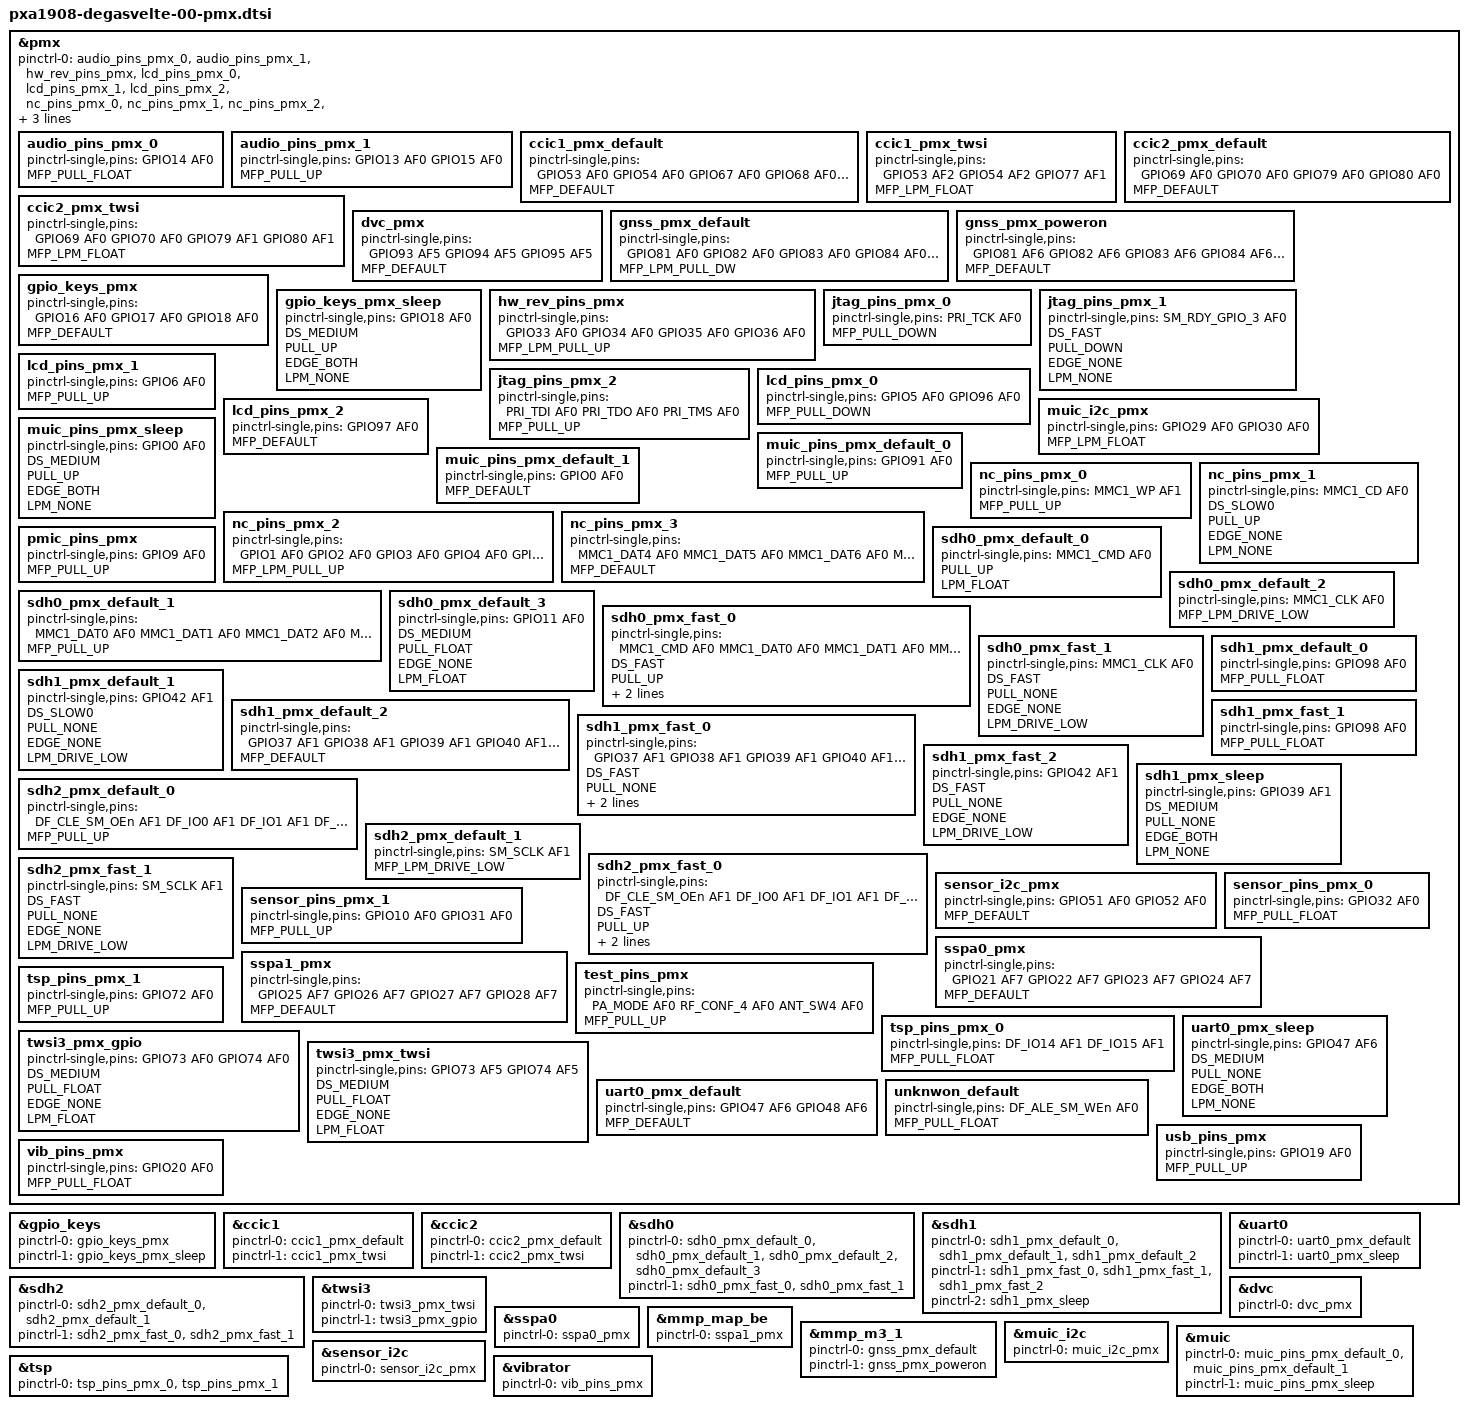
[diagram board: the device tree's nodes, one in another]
/* arch/arm64/boot/dts/pxa1908-degasvelte-00-pmx.dtsi
 *
 *	Copyright (C) 2014 Marvell Technology Group Ltd.
 *	Copyright (C) 2014 Samsung Electronics Co, Ltd.
 *
 *	Most of configurations are taken from J1-LTE
 *
 *	This program is free software; you can redistribute it and/or modify
 *	it under the terms of the GNU General Public License version 2 as
 *	published by the Free Software Foundation.
 */

#ifndef __PXA1908_DEGASVELTE_00_PMX_DTSI__
#define __PXA1908_DEGASVELTE_00_PMX_DTSI__

&pmx {
	/* >>>BEGIN: audio_pins_pmx */
	audio_pins_pmx_0: audio_pins_pmx_0 {	/* default */
		pinctrl-single,pins = <
			GPIO14			AF0	/* EAR_G_DET (GPIO[14]) */
		>;
		MFP_PULL_FLOAT;
	};

	audio_pins_pmx_1: audio_pins_pmx_1 {	/* default */
		pinctrl-single,pins = <
			GPIO13			AF0	/* EAR_SW (GPIO[13]) */
			GPIO15			AF0	/* EAR_DET_3.5 (GPIO[15]) */
		>;
		MFP_PULL_UP;
	};
	/* <<<END: audio_pins_pmx */

	/* >>>BEGIN: ccic1_pmx_default */
	ccic1_pmx_default: ccic1_pmx_default {	/* default */
		pinctrl-single,pins = <
			GPIO53			AF0	/* 3M_CAM_SCL_1P8 (GPIO[53]) */
			GPIO54			AF0	/* 3M_CAM_SDA_1P8 (GPIO[54]) */
			GPIO67			AF0	/* 3M_CAM_nRST (GPIO[67]) */
			GPIO68			AF0	/* 3M_CAM_STBY (GPIO[68]) */
			GPIO77			AF1	/* CAM_MCLK (CAM_MCLK) */
		>;
		MFP_DEFAULT;
	};
	/* <<<END: ccic1_pmx_default */

	/* >>>BEGIN: ccic1_pmx_twsi */
	ccic1_pmx_twsi: ccic1_pmx_twsi {	/* twsi */
		pinctrl-single,pins = <
			GPIO53			AF2	/* 3M_CAM_SCL_1P8 (CI2C_SCL_1) */
			GPIO54			AF2	/* 3M_CAM_SDA_1P8 (CI2C_SDA_1) */
			GPIO77			AF1	/* CAM_MCLK (CAM_MCLK) */
		>;
		MFP_LPM_FLOAT;
	};
	/* <<<END: ccic1_pmx_twsi */

	/* >>>BEGIN: ccic2_pmx_default */
	ccic2_pmx_default: ccic2_pmx_default {	/* default */
		pinctrl-single,pins = <
			GPIO69			AF0	/* VT_CAM_nRST (GPIO[69]) */
			GPIO70			AF0	/* VT_CAM_nSTBY (GPIO[70]) */
			GPIO79			AF0	/* VT_CAM_SCL_1P8 (GPIO[79]) */
			GPIO80			AF0	/* VT_CAM_SDA_1P8 (GPIO[80]) */
		>;
		MFP_DEFAULT;
	};
	/* <<<END: ccic2_pmx_default */

	/* >>>BEGIN: ccic2_pmx_twsi */
	ccic2_pmx_twsi: ccic2_pmx_twsi {	/* twsi */
		pinctrl-single,pins = <
			GPIO69			AF0	/* VT_CAM_nRST (GPIO[69]) */
			GPIO70			AF0	/* VT_CAM_nSTBY (GPIO[70]) */
			GPIO79			AF1	/* VT_CAM_SCL_1P8 (CI2C_SCL_1) */
			GPIO80			AF1	/* VT_CAM_SDA_1P8 (CI2C_SDA_1) */
		>;
		MFP_LPM_FLOAT;
	};
	/* <<<END: ccic2_pmx_twsi */

	/* >>>BEGIN: dvc_pmx */
	dvc_pmx: dvc_pmx {	/* default */
		pinctrl-single,pins = <
			GPIO93			AF5	/* DVC2 (DVL[1]) */
			GPIO94			AF5	/* DVC1 (DVL[0]) */
			GPIO95			AF5	/* DVC3 (DVL[2]) */
		>;
		MFP_DEFAULT;
	};
	/* <<<END: dvc_pmx */

	/* >>>BEGIN: gnss_pmx_default */
	gnss_pmx_default: gnss_pmx_default {	/* default */
		pinctrl-single,pins = <
			GPIO81			AF0	/* GPS_IRQ (GPIO[81]) */
			GPIO82			AF0	/* GPS_RST (GPIO[82]) */
			GPIO83			AF0	/* GPS_CS_N (GPIO[83]) */
			GPIO84			AF0	/* GPS_SYNC_CLK (GPIO[84]) */
			GPIO85			AF0	/* GNSS_RF_SDIN (GPIO[85]) */
		>;
		MFP_LPM_PULL_DW;
	};
	/* <<<END: gnss_pmx_default */

	/* >>>BEGIN: gnss_pmx_poweron */
	gnss_pmx_poweron: gnss_pmx_poweron {	/* poweron */
		pinctrl-single,pins = <
			GPIO81			AF6	/* GPS_IRQ (GNSS_RF_IRQ) */
			GPIO82			AF6	/* GPS_RST (GNSS_RF_RESETn) */
			GPIO83			AF6	/* GPS_CS_N (GNSS_RF_CSn) */
			GPIO84			AF6	/* GPS_SYNC_CLK (GNSS_RF_CLK) */
			GPIO85			AF6	/* GNSS_RF_SDIN (GNSS_RF_DATA) */
		>;
		MFP_DEFAULT;
	};
	/* <<<END: gnss_pmx_poweron */

	/* >>>BEGIN: gpio_keys_pmx */
	gpio_keys_pmx: gpio_keys_pmx {	/* default */
		pinctrl-single,pins = <
			GPIO16			AF0	/* VOL_UP (GPIO[16]) */
			GPIO17			AF0	/* VOL_DN (GPIO[17]) */
			GPIO18			AF0	/* HOME_KEY (GPIO[18]) */
		>;
		MFP_DEFAULT;
	};
	/* <<<END: gpio_keys_pmx */

	/* >>>BEGIN: gpio_keys_pmx_sleep */
	gpio_keys_pmx_sleep: gpio_keys_pmx_sleep {	/* sleep */
		pinctrl-single,pins = <
			GPIO18			AF0	/* HOME_KEY (GPIO[18]) */
		>;
		DS_MEDIUM; PULL_UP; EDGE_BOTH; LPM_NONE;
	};
	/* <<<END: gpio_keys_pmx_sleep */

	/* >>>BEGIN: hw_rev_pins_pmx */
	hw_rev_pins_pmx: hw_rev_pins_pmx {	/* default */
		pinctrl-single,pins = <
			GPIO33			AF0	/* HW_REV0 (GPIO[33]) */
			GPIO34			AF0	/* HW_REV1 (GPIO[34]) */
			GPIO35			AF0	/* HW_REV2 (GPIO[35]) */
			GPIO36			AF0	/* HW_REV3 (GPIO[36]) */
		>;
		MFP_LPM_PULL_UP;
	};
	/* <<<END: hw_rev_pins_pmx */

	/* >>>BEGIN: jtag_pins_pmx */
	jtag_pins_pmx_0: jtag_pins_pmx_0 {	/* default */
		pinctrl-single,pins = <
			PRI_TCK			AF0	/* JTAG_TCK (PRI_TCK) */
		>;
		MFP_PULL_DOWN;
	};

	jtag_pins_pmx_1: jtag_pins_pmx_1 {	/* default */
		pinctrl-single,pins = <
			SM_RDY_GPIO_3		AF0	/* AP_USB_BOOT (SM_RDY) */
		>;
		DS_FAST; PULL_DOWN; EDGE_NONE; LPM_NONE;
	};

	jtag_pins_pmx_2: jtag_pins_pmx_2 {	/* default */
		pinctrl-single,pins = <
			PRI_TDI			AF0	/* JTAG_TDI (PRI_TDI) */
			PRI_TDO			AF0	/* JTAG_TDO (PRI_TDO) */
			PRI_TMS			AF0	/* JTAG_TMS (PRI_TMS) */
		>;
		MFP_PULL_UP;
	};
	/* <<<END: jtag_pins_pmx */

	/* >>>BEGIN: lcd_pins_pmx */
	lcd_pins_pmx_0: lcd_pins_pmx_0 {	/* default */
		pinctrl-single,pins = <
			GPIO5			AF0	/* LCD_3V3_EN (GPIO[5]) */
			GPIO96			AF0	/* LCD_nRST (GPIO[96]) */
		>;
		MFP_PULL_DOWN;
	};

	lcd_pins_pmx_1: lcd_pins_pmx_1 {	/* default */
		pinctrl-single,pins = <
			GPIO6			AF0	/* LCD_ESD_DET (GPIO[6]) */
		>;
		MFP_PULL_UP;
	};

	lcd_pins_pmx_2: lcd_pins_pmx_2 {	/* default */
		pinctrl-single,pins = <
			GPIO97			AF0	/* LCD_BLIC_ON (GPIO[97]) */
		>;
		MFP_DEFAULT;
	};
	/* <<<END: lcd_pins_pmx */

	/* >>>BEGIN: muic_i2c_pmx */
	muic_i2c_pmx: muic_i2c_pmx {	/* default */
		pinctrl-single,pins = <
			GPIO29			AF0	/* MUIC_SCL_1P8 (GPIO[29]) */
			GPIO30			AF0	/* MUIC_SDA_1P8 (GPIO[30]) */
		>;
		MFP_LPM_FLOAT;
	};
	/* <<<END: muic_i2c_pmx */

	/* >>>BEGIN: muic_pins_pmx_default */
	muic_pins_pmx_default_0: muic_pins_pmx_default_0 {	/* default */
		pinctrl-single,pins = <
			GPIO91			AF0	/* UART_BOOT_ON (GPIO[91]) */
		>;
		MFP_PULL_UP;
	};

	muic_pins_pmx_default_1: muic_pins_pmx_default_1 {	/* default */
		pinctrl-single,pins = <
			GPIO0			AF0	/* MUIC_INT (GPIO[0]) */
		>;
		MFP_DEFAULT;
	};
	/* <<<END: muic_pins_pmx_default */

	/* >>>BEGIN: muic_pins_pmx_sleep */
	muic_pins_pmx_sleep: muic_pins_pmx_sleep {	/* sleep */
		pinctrl-single,pins = <
			GPIO0			AF0	/* MUIC_INT (GPIO[0]) */
		>;
		DS_MEDIUM; PULL_UP; EDGE_BOTH; LPM_NONE;
	};
	/* <<<END: muic_pins_pmx_sleep */

	/* >>>BEGIN: nc_pins_pmx */
	nc_pins_pmx_0: nc_pins_pmx_0 {	/* default */
		pinctrl-single,pins = <
			MMC1_WP			AF1	/* NC (GPIO[99]) */
		>;
		MFP_PULL_UP;
	};

	nc_pins_pmx_1: nc_pins_pmx_1 {	/* default */
		pinctrl-single,pins = <
			MMC1_CD			AF0	/* NC (MMC1_CD) */
		>;
		DS_SLOW0; PULL_UP; EDGE_NONE; LPM_NONE;
	};

	nc_pins_pmx_2: nc_pins_pmx_2 {	/* default */
		pinctrl-single,pins = <
			GPIO1			AF0	/* NC (GPIO[1]) */
			GPIO2			AF0	/* NC (GPIO[2]) */
			GPIO3			AF0	/* NC (GPIO[3]) */
			GPIO4			AF0	/* NC (GPIO[4]) */
			GPIO7			AF0	/* NC (GPIO[7]) */
			GPIO8			AF0	/* NC (GPIO[8]) */
			GPIO12			AF0	/* NC (GPIO[12]) */
			GPIO43			AF0	/* NC (GPIO[43]) */
			GPIO44			AF0	/* NC (GPIO[44]) */
			GPIO45			AF0	/* NC (GPIO[45]) */
			GPIO46			AF0	/* NC (GPIO[46]) */
			GPIO49			AF0	/* NC (GPIO[49]) */
			GPIO50			AF0	/* NC (GPIO[50]) */
			GPIO71			AF0	/* NC (GPIO[71]) */
			GPIO75			AF0	/* NC (GPIO[75]) */
			GPIO76			AF0	/* NC (GPIO[76]) */
			GPIO78			AF0	/* NC (GPIO[78]) */
			GPIO86			AF0	/* NC (GPIO[86]) */
			GPIO87			AF0	/* NC (GPIO[87]) */
			GPIO88			AF0	/* NC (GPIO[88]) */
			GPIO89			AF0	/* NC (GPIO[89]) */
			GPIO90			AF0	/* NC (GPIO[90]) */
			GPIO92			AF0	/* NC (GPIO[92]) */
			GPIO124			AF0	/* NC (GPIO[124]) */
			SM_ADV			AF1	/* NC (GPIO[0]) */
			SM_ADVMUX		AF1	/* NC (GPIO[2]) */
			SM_BE0			AF0	/* NC (GPIO[126]) */
			SM_BE1			AF0	/* NC (GPIO[127]) */
			SM_nCS0			AF1	/* NC (GPIO[103]) */
			SM_nCS1			AF1	/* NC (GPIO[104]) */
			DF_nCS1_SM_nCS3		AF1	/* NC (GPIO[102]) */
			DF_RDY0			AF1	/* NC (GPIO[108]) */
			DF_RDY1			AF1	/* NC (GPIO[1]) */
			DF_REn			AF0	/* NC (ND_REn) */
			DF_WEn			AF0	/* NC (ND_WEn) */
		>;
		MFP_LPM_PULL_UP;
	};

	nc_pins_pmx_3: nc_pins_pmx_3 {	/* default */
		pinctrl-single,pins = <
			MMC1_DAT4		AF0	/* NC (MMC1_DAT[4]) */
			MMC1_DAT5		AF0	/* NC (MMC1_DAT[5]) */
			MMC1_DAT6		AF0	/* NC (MMC1_DAT[6]) */
			MMC1_DAT7		AF0	/* NC (MMC1_DAT[7]) */
			DF_IO8			AF1	/* NC (GPIO[100]) */
			DF_IO9			AF1	/* NC (GPIO[66]) */
			DF_IO10			AF1	/* NC (GPIO[65]) */
			DF_IO11			AF1	/* NC (GPIO[64]) */
			DF_IO12			AF1	/* NC (GPIO[63]) */
			DF_IO13			AF1	/* NC (GPIO[62]) */
		>;
		MFP_DEFAULT;
	};
	/* <<<END: nc_pins_pmx */

	/* >>>BEGIN: pmic_pins_pmx */
	pmic_pins_pmx: pmic_pins_pmx {	/* default */
		pinctrl-single,pins = <
			GPIO9			AF0	/* PA_EN (GPIO[9]) */
		>;
		MFP_PULL_UP;
	};
	/* <<<END: pmic_pins_pmx */

	/* >>>BEGIN: sdh0_pmx_default */
	sdh0_pmx_default_0: sdh0_pmx_default_0 {	/* default */
		pinctrl-single,pins = <
			MMC1_CMD		AF0	/* T_FLASH_CMD (MMC1_CMD) */
		>;
		PULL_UP; LPM_FLOAT;
	};

	sdh0_pmx_default_1: sdh0_pmx_default_1 {	/* default */
		pinctrl-single,pins = <
			MMC1_DAT0		AF0	/* T_FLASH_D0 (MMC1_DAT[0]) */
			MMC1_DAT1		AF0	/* T_FLASH_D1 (MMC1_DAT[1]) */
			MMC1_DAT2		AF0	/* T_FLASH_D2 (MMC1_DAT[2]) */
			MMC1_DAT3		AF0	/* T_FLASH_D3 (MMC1_DAT[3]) */
		>;
		MFP_PULL_UP;
	};

	sdh0_pmx_default_2: sdh0_pmx_default_2 {	/* default */
		pinctrl-single,pins = <
			MMC1_CLK		AF0	/* T_FLASH_CLK (MMC1_CLK) */
		>;
		MFP_LPM_DRIVE_LOW;
	};

	sdh0_pmx_default_3: sdh0_pmx_default_3 {	/* default */
		pinctrl-single,pins = <
			GPIO11			AF0	/* T_FLASH_DET_N (GPIO[11]) */
		>;
		DS_MEDIUM; PULL_FLOAT; EDGE_NONE; LPM_FLOAT;
	};
	/* <<<END: sdh0_pmx_default */

	/* >>>BEGIN: sdh0_pmx_fast */
	sdh0_pmx_fast_0: sdh0_pmx_fast_0 {	/* fast */
		pinctrl-single,pins = <
			MMC1_CMD		AF0	/* T_FLASH_CMD (MMC1_CMD) */
			MMC1_DAT0		AF0	/* T_FLASH_D0 (MMC1_DAT[0]) */
			MMC1_DAT1		AF0	/* T_FLASH_D1 (MMC1_DAT[1]) */
			MMC1_DAT2		AF0	/* T_FLASH_D2 (MMC1_DAT[2]) */
			MMC1_DAT3		AF0	/* T_FLASH_D3 (MMC1_DAT[3]) */
		>;
		DS_FAST; PULL_UP; EDGE_NONE; LPM_NONE;
	};

	sdh0_pmx_fast_1: sdh0_pmx_fast_1 {	/* fast */
		pinctrl-single,pins = <
			MMC1_CLK		AF0	/* T_FLASH_CLK (MMC1_CLK) */
		>;
		DS_FAST; PULL_NONE; EDGE_NONE; LPM_DRIVE_LOW;
	};
	/* <<<END: sdh0_pmx_fast */

	/* >>>BEGIN: sdh1_pmx_default */
	sdh1_pmx_default_0: sdh1_pmx_default_0 {	/* default */
		pinctrl-single,pins = <
			GPIO98			AF0	/* WLAN_PDn (GPIO[98]) */
		>;
		MFP_PULL_FLOAT;
	};

	sdh1_pmx_default_1: sdh1_pmx_default_1 {	/* default */
		pinctrl-single,pins = <
			GPIO42			AF1	/* WLAN_CLK (MMC2_CLK) */
		>;
		DS_SLOW0; PULL_NONE; EDGE_NONE; LPM_DRIVE_LOW;
	};

	sdh1_pmx_default_2: sdh1_pmx_default_2 {	/* default */
		pinctrl-single,pins = <
			GPIO37			AF1	/* WLAN_D3 (MMC2_DAT[3]) */
			GPIO38			AF1	/* WLAN_D2 (MMC2_DAT[2]) */
			GPIO39			AF1	/* WLAN_D1 (MMC2_DAT[1]) */
			GPIO40			AF1	/* WLAN_D0 (MMC2_DAT[0]) */
			GPIO41			AF1	/* WLAN_CMD (MMC2_CMD) */
		>;
		MFP_DEFAULT;
	};
	/* <<<END: sdh1_pmx_default */

	/* >>>BEGIN: sdh1_pmx_fast */
	sdh1_pmx_fast_0: sdh1_pmx_fast_0 {	/* fast */
		pinctrl-single,pins = <
			GPIO37			AF1	/* WLAN_D3 (MMC2_DAT[3]) */
			GPIO38			AF1	/* WLAN_D2 (MMC2_DAT[2]) */
			GPIO39			AF1	/* WLAN_D1 (MMC2_DAT[1]) */
			GPIO40			AF1	/* WLAN_D0 (MMC2_DAT[0]) */
			GPIO41			AF1	/* WLAN_CMD (MMC2_CMD) */
		>;
		DS_FAST; PULL_NONE; EDGE_NONE; LPM_NONE;
	};

	sdh1_pmx_fast_1: sdh1_pmx_fast_1 {	/* fast */
		pinctrl-single,pins = <
			GPIO98			AF0	/* WLAN_PDn (GPIO[98]) */
		>;
		MFP_PULL_FLOAT;
	};

	sdh1_pmx_fast_2: sdh1_pmx_fast_2 {	/* fast */
		pinctrl-single,pins = <
			GPIO42			AF1	/* WLAN_CLK (MMC2_CLK) */
		>;
		DS_FAST; PULL_NONE; EDGE_NONE; LPM_DRIVE_LOW;
	};
	/* <<<END: sdh1_pmx_fast */

	/* >>>BEGIN: sdh1_pmx_sleep */
	sdh1_pmx_sleep: sdh1_pmx_sleep {	/* sleep */
		pinctrl-single,pins = <
			GPIO39			AF1	/* WLAN_D1 (MMC2_DAT[1]) */
		>;
		DS_MEDIUM; PULL_NONE; EDGE_BOTH; LPM_NONE;
	};
	/* <<<END: sdh1_pmx_sleep */

	/* >>>BEGIN: sdh2_pmx_default */
	sdh2_pmx_default_0: sdh2_pmx_default_0 {	/* default */
		pinctrl-single,pins = <
			DF_CLE_SM_OEn		AF1	/* EMMC_CMD (MMC3_CMD) */
			DF_IO0			AF1	/* EMMC_D0 (MMC3_DAT[0]) */
			DF_IO1			AF1	/* EMMC_D1 (MMC3_DAT[1]) */
			DF_IO2			AF1	/* EMMC_D2 (MMC3_DAT[2]) */
			DF_IO3			AF1	/* EMMC_D3 (MMC3_DAT[3]) */
			DF_IO4			AF1	/* EMMC_D4 (MMC3_DAT[4]) */
			DF_IO5			AF1	/* EMMC_D5 (MMC3_DAT[5]) */
			DF_IO6			AF1	/* EMMC_D6 (MMC3_DAT[6]) */
			DF_IO7			AF1	/* EMMC_D7 (MMC3_DAT[7]) */
		>;
		MFP_PULL_UP;
	};

	sdh2_pmx_default_1: sdh2_pmx_default_1 {	/* default */
		pinctrl-single,pins = <
			SM_SCLK			AF1	/* EMMC_CLK (MMC3_CLK) */
		>;
		MFP_LPM_DRIVE_LOW;
	};
	/* <<<END: sdh2_pmx_default */

	/* >>>BEGIN: sdh2_pmx_fast */
	sdh2_pmx_fast_0: sdh2_pmx_fast_0 {	/* fast */
		pinctrl-single,pins = <
			DF_CLE_SM_OEn		AF1	/* EMMC_CMD (MMC3_CMD) */
			DF_IO0			AF1	/* EMMC_D0 (MMC3_DAT[0]) */
			DF_IO1			AF1	/* EMMC_D1 (MMC3_DAT[1]) */
			DF_IO2			AF1	/* EMMC_D2 (MMC3_DAT[2]) */
			DF_IO3			AF1	/* EMMC_D3 (MMC3_DAT[3]) */
			DF_IO4			AF1	/* EMMC_D4 (MMC3_DAT[4]) */
			DF_IO5			AF1	/* EMMC_D5 (MMC3_DAT[5]) */
			DF_IO6			AF1	/* EMMC_D6 (MMC3_DAT[6]) */
			DF_IO7			AF1	/* EMMC_D7 (MMC3_DAT[7]) */
		>;
		DS_FAST; PULL_UP; EDGE_NONE; LPM_NONE;
	};

	sdh2_pmx_fast_1: sdh2_pmx_fast_1 {	/* fast */
		pinctrl-single,pins = <
			SM_SCLK			AF1	/* EMMC_CLK (MMC3_CLK) */
		>;
		DS_FAST; PULL_NONE; EDGE_NONE; LPM_DRIVE_LOW;
	};
	/* <<<END: sdh2_pmx_fast */

	/* >>>BEGIN: sensor_i2c_pmx */
	sensor_i2c_pmx: sensor_i2c_pmx {	/* default */
		pinctrl-single,pins = <
			GPIO51			AF0	/* SENSOR_SCL_1P8 (GPIO[51]) */
			GPIO52			AF0	/* SENSOR_SDA_1P8 (GPIO[52]) */
		>;
		MFP_DEFAULT;
	};
	/* <<<END: sensor_i2c_pmx */

	/* >>>BEGIN: sensor_pins_pmx */
	sensor_pins_pmx_0: sensor_pins_pmx_0 {	/* default */
		pinctrl-single,pins = <
			GPIO32			AF0	/* RF_TOUCH_INT (GPIO[32]) */
		>;
		MFP_PULL_FLOAT;
	};

	sensor_pins_pmx_1: sensor_pins_pmx_1 {	/* default */
		pinctrl-single,pins = <
			GPIO10			AF0	/* ACC_INT_N (GPIO[10]) */
			GPIO31			AF0	/* CONDUCTION_DET (GPIO[31]) */
		>;
		MFP_PULL_UP;
	};
	/* <<<END: sensor_pins_pmx */

	/* >>>BEGIN: sspa0_pmx */
	sspa0_pmx: sspa0_pmx {	/* default */
		pinctrl-single,pins = <
			GPIO21			AF7	/* I2S_BCK (SSPA1_CLK) */
			GPIO22			AF7	/* I2S_SYNC (SSPA1_FRM) */
			GPIO23			AF7	/* I2S_D_OUT (SSPA1_TXD) */
			GPIO24			AF7	/* I2S_D_IN (SSPA1_RXD) */
		>;
		MFP_DEFAULT;
	};
	/* <<<END: sspa0_pmx */

	/* >>>BEGIN: sspa1_pmx */
	sspa1_pmx: sspa1_pmx {	/* default */
		pinctrl-single,pins = <
			GPIO25			AF7	/* BT_PCM_CLK (SSPA2_CLK) */
			GPIO26			AF7	/* BT_PCM_SYNC (SSPA2_FRM) */
			GPIO27			AF7	/* BT_PCM_TXD (SSPA2_TXD) */
			GPIO28			AF7	/* BT_PCM_RXD (SSPA2_RXD) */
		>;
		MFP_DEFAULT;
	};
	/* <<<END: sspa1_pmx */

	/* >>>BEGIN: test_pins_pmx */
	test_pins_pmx: test_pins_pmx {	/* default */
		pinctrl-single,pins = <
			PA_MODE			AF0	/* TP_PA_MODE (PA_MODE) */
			RF_CONF_4		AF0	/* TP_RF_CONT[300 (RF_CONF[4]) */
			ANT_SW4			AF0	/* TP_U300 (ANT_SW4) */
		>;
		MFP_PULL_UP;
	};
	/* <<<END: test_pins_pmx */

	/* >>>BEGIN: tsp_pins_pmx */
	tsp_pins_pmx_0: tsp_pins_pmx_0 {	/* default */
		pinctrl-single,pins = <
			DF_IO14			AF1	/* TSP_VENDOR_1 (GPIO[61]) */
			DF_IO15			AF1	/* TSP_VENDOR_2 (GPIO[60]) */
		>;
		MFP_PULL_FLOAT;
	};

	tsp_pins_pmx_1: tsp_pins_pmx_1 {	/* default */
		pinctrl-single,pins = <
			GPIO72			AF0	/* TSP_INT (GPIO[72]) */
		>;
		MFP_PULL_UP;
	};
	/* <<<END: tsp_pins_pmx */

	/* >>>BEGIN: twsi3_pmx_gpio */
	twsi3_pmx_gpio: twsi3_pmx_gpio {	/* gpio */
		pinctrl-single,pins = <
			GPIO73			AF0	/* TSP_SCL_1P8 (GPIO[73]) */
			GPIO74			AF0	/* TSP_SDA_1P8 (GPIO[74]) */
		>;
		DS_MEDIUM; PULL_FLOAT; EDGE_NONE; LPM_FLOAT;
	};
	/* <<<END: twsi3_pmx_gpio */

	/* >>>BEGIN: twsi3_pmx_twsi */
	twsi3_pmx_twsi: twsi3_pmx_twsi {	/* default */
		pinctrl-single,pins = <
			GPIO73			AF5	/* TSP_SCL_1P8 (CI2C_SCL_3) */
			GPIO74			AF5	/* TSP_SDA_1P8 (CI2C_SDA_3) */
		>;
		DS_MEDIUM; PULL_FLOAT; EDGE_NONE; LPM_FLOAT;
	};
	/* <<<END: twsi3_pmx_twsi */

	/* >>>BEGIN: uart0_pmx_default */
	uart0_pmx_default: uart0_pmx_default {	/* default */
		pinctrl-single,pins = <
			GPIO47			AF6	/* UART_RXD (UART2_RXD) */
			GPIO48			AF6	/* UART_TXD (UART2_TXD) */
		>;
		MFP_DEFAULT;
	};
	/* <<<END: uart0_pmx_default */

	/* >>>BEGIN: uart0_pmx_sleep */
	uart0_pmx_sleep: uart0_pmx_sleep {	/* sleep */
		pinctrl-single,pins = <
			GPIO47			AF6	/* UART_RXD (UART2_RXD) */
		>;
		DS_MEDIUM; PULL_NONE; EDGE_BOTH; LPM_NONE;
	};
	/* <<<END: uart0_pmx_sleep */

	/* >>>BEGIN: unknwon_default */
	unknwon_default: unknwon_default {	/* default */
		pinctrl-single,pins = <
			DF_ALE_SM_WEn		AF0	/* ND_ALE_SM_WEn (GPIO[107]) */
		>;
		MFP_PULL_FLOAT;
	};
	/* <<<END: unknwon_default */

	/* >>>BEGIN: usb_pins_pmx */
	usb_pins_pmx: usb_pins_pmx {	/* default */
		pinctrl-single,pins = <
			GPIO19			AF0	/* USB_ID_AP (GPIO[19]) */
		>;
		MFP_PULL_UP;
	};
	/* <<<END: usb_pins_pmx */

	/* >>>BEGIN: vib_pins_pmx */
	vib_pins_pmx: vib_pins_pmx {	/* default */
		pinctrl-single,pins = <
			GPIO20			AF0	/* MOTOR_EN (GPIO[20]) */
		>;
		MFP_PULL_FLOAT;
	};
	/* <<<END: vib_pins_pmx */

};

/* >>>BEGIN: gpio_keys */
&gpio_keys {
	pinctrl-names = "default", "sleep";
	pinctrl-0 = <&gpio_keys_pmx>;
	pinctrl-1 = <&gpio_keys_pmx_sleep>;
};
/* <<<END: gpio_keys */

/* >>>BEGIN: ccic1 */
&ccic1 {
	pinctrl-names = "default", "twsi";
	pinctrl-0 = <&ccic1_pmx_default>;
	pinctrl-1 = <&ccic1_pmx_twsi>;
};
/* <<<END: ccic1 */

/* >>>BEGIN: ccic2 */
&ccic2 {
	pinctrl-names = "default", "twsi";
	pinctrl-0 = <&ccic2_pmx_default>;
	pinctrl-1 = <&ccic2_pmx_twsi>;
};
/* <<<END: ccic2 */

/* >>>BEGIN: sdh0 */
&sdh0 {
	pinctrl-names = "default", "fast";
	pinctrl-0 = <&sdh0_pmx_default_0 &sdh0_pmx_default_1 &sdh0_pmx_default_2 &sdh0_pmx_default_3>;
	pinctrl-1 = <&sdh0_pmx_fast_0 &sdh0_pmx_fast_1>;
};
/* <<<END: sdh0 */

/* >>>BEGIN: sdh1 */
&sdh1 {
	pinctrl-names = "default", "fast", "sleep";
	pinctrl-0 = <&sdh1_pmx_default_0 &sdh1_pmx_default_1 &sdh1_pmx_default_2>;
	pinctrl-1 = <&sdh1_pmx_fast_0 &sdh1_pmx_fast_1 &sdh1_pmx_fast_2>;
	pinctrl-2 = <&sdh1_pmx_sleep>;
};
/* <<<END: sdh1 */

/* >>>BEGIN: sdh2 */
&sdh2 {
	pinctrl-names = "default", "fast";
	pinctrl-0 = <&sdh2_pmx_default_0 &sdh2_pmx_default_1>;
	pinctrl-1 = <&sdh2_pmx_fast_0 &sdh2_pmx_fast_1>;
};
/* <<<END: sdh2 */

/* >>>BEGIN: uart0 */
&uart0 {
	pinctrl-names = "default", "sleep";
	pinctrl-0 = <&uart0_pmx_default>;
	pinctrl-1 = <&uart0_pmx_sleep>;
};
/* <<<END: uart0 */

/* >>>BEGIN: twsi3 */
&twsi3 {
	pinctrl-names = "default", "gpio";
	pinctrl-0 = <&twsi3_pmx_twsi>;
	pinctrl-1 = <&twsi3_pmx_gpio>;
};
/* <<<END: twsi3 */

/* >>>BEGIN: dvc */
&dvc {
	pinctrl-names = "default";
	pinctrl-0 = <&dvc_pmx>;
};
/* <<<END: dvc */

/* >>>BEGIN: sspa0 */
&sspa0 {
	pinctrl-names = "default";
	pinctrl-0 = <&sspa0_pmx>;
};
/* <<<END: sspa0 */

/* >>>BEGIN: mmp_map_be */
&mmp_map_be {
	pinctrl-names = "default";
	pinctrl-0 = <&sspa1_pmx>;
};
/* <<<END: mmp_map_be */

/* >>>BEGIN: mmp_m3_1 */
&mmp_m3_1 {
	pinctrl-names = "default", "poweron";
	pinctrl-0 = <&gnss_pmx_default>;
	pinctrl-1 = <&gnss_pmx_poweron>;
};
/* <<<END: mmp_m3_1 */

/* >>>BEGIN: muic_i2c */
&muic_i2c {
	pinctrl-names = "default";
	pinctrl-0 = <&muic_i2c_pmx>;
};
/* <<<END: muic_i2c */

/* >>>BEGIN: muic */
&muic {
	pinctrl-names = "default", "sleep";
	pinctrl-0 = <&muic_pins_pmx_default_0 &muic_pins_pmx_default_1>;
	pinctrl-1 = <&muic_pins_pmx_sleep>;
};
/* <<<END: muic */

/* >>>BEGIN: sensor_i2c */
&sensor_i2c {
	pinctrl-names = "default";
	pinctrl-0 = <&sensor_i2c_pmx>;
};
/* <<<END: sensor_i2c */

/* >>>BEGIN: tsp */
&tsp {
	pinctrl-names = "default";
	pinctrl-0 = <&tsp_pins_pmx_0 &tsp_pins_pmx_1>;
};
/* <<<END: tsp */

/* >>>BEGIN: vibrator */
&vibrator {
	pinctrl-names = "default";
	pinctrl-0 = <&vib_pins_pmx>;
};
/* <<<END: vibrator */

/* >>>BEGIN: pmx */
&pmx {
	pinctrl-names = "default";
	pinctrl-0 = <	&audio_pins_pmx_0 &audio_pins_pmx_1
			&hw_rev_pins_pmx /* &jtag_pins_pmx_0 &jtag_pins_pmx_1 &jtag_pins_pmx_2 */
			&lcd_pins_pmx_0 &lcd_pins_pmx_1 &lcd_pins_pmx_2
			&nc_pins_pmx_0 &nc_pins_pmx_1 &nc_pins_pmx_2 &nc_pins_pmx_3 &pmic_pins_pmx
			&sensor_pins_pmx_0 &sensor_pins_pmx_1
			&test_pins_pmx
			&unknwon_default
			&usb_pins_pmx>;
};
/* <<<END: pmx */


#endif	/*__PXA1908_DEGASVELTE_00_PMX_DTSI__*/
